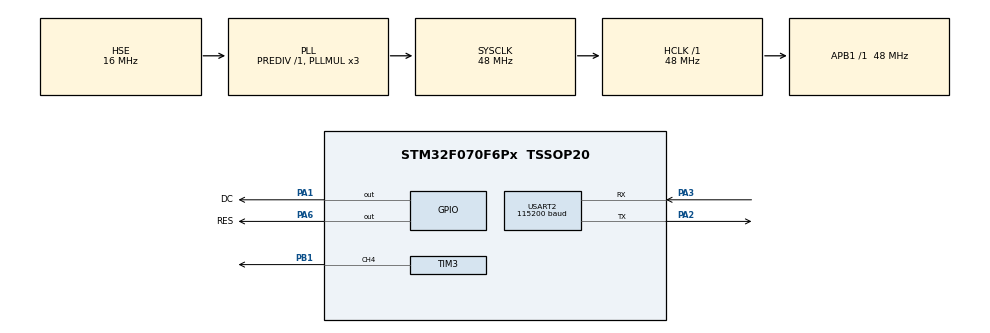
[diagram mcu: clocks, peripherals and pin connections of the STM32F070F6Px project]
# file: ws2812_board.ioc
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Dma.Request0=TIM3_CH4/UP
Dma.TIM3_CH4/UP.0.Direction=DMA_MEMORY_TO_PERIPH
Dma.TIM3_CH4/UP.0.Instance=DMA1_Channel3
Dma.TIM3_CH4/UP.0.MemDataAlignment=DMA_MDATAALIGN_WORD
Dma.TIM3_CH4/UP.0.MemInc=DMA_MINC_ENABLE
Dma.TIM3_CH4/UP.0.Mode=DMA_NORMAL
Dma.TIM3_CH4/UP.0.PeriphDataAlignment=DMA_PDATAALIGN_WORD
Dma.TIM3_CH4/UP.0.PeriphInc=DMA_PINC_DISABLE
Dma.TIM3_CH4/UP.0.Priority=DMA_PRIORITY_VERY_HIGH
Mcu.Family=STM32F0
Mcu.Name=STM32F070F6Px
Mcu.Package=TSSOP20
NVIC.DMA1_Channel2_3_IRQn=true\:0\:0\:false\:false\:true\:false\:true
NVIC.TIM3_IRQn=true\:0\:0\:false\:false\:true\:true\:true
PA1.GPIO_Label=DC
PA1.GPIO_Speed=GPIO_SPEED_FREQ_HIGH
PA1.Signal=GPIO_Output
PA13.Mode=Serial_Wire
PA13.Signal=SYS_SWDIO
PA14.Mode=Serial_Wire
PA14.Signal=SYS_SWCLK
PA2.Mode=Asynchronous
PA2.Signal=USART2_TX
PA3.Mode=Asynchronous
PA3.Signal=USART2_RX
PA6.GPIO_Label=RES
PA6.GPIO_Speed=GPIO_SPEED_FREQ_HIGH
PA6.Signal=GPIO_Output
PB1.Signal=S_TIM3_CH4
PF0-OSC_IN.Mode=HSE-External-Oscillator
PF0-OSC_IN.Signal=RCC_OSC_IN
PF1-OSC_OUT.Mode=HSE-External-Oscillator
PF1-OSC_OUT.Signal=RCC_OSC_OUT
ProjectManager.HeapSize=0x0
ProjectManager.StackSize=0x400
ProjectManager.TargetToolchain=MDK-ARM V5.32
RCC.AHBFreq_Value=48000000
RCC.APB1Freq_Value=48000000
RCC.APB1TimFreq_Value=48000000
RCC.HCLKFreq_Value=48000000
RCC.HSE_VALUE=16000000
RCC.PLLMUL=RCC_PLL_MUL3
RCC.PLLSourceVirtual=RCC_PLLSOURCE_HSE
RCC.SYSCLKFreq_VALUE=48000000
RCC.SYSCLKSource=RCC_SYSCLKSOURCE_PLLCLK
SH.S_TIM3_CH4.0=TIM3_CH4,PWM Generation4 CH4
TIM3.Channel-PWM\ Generation4\ CH4=TIM_CHANNEL_4
TIM3.Period=60-1
TIM3.Prescaler=1-1
USART2.BaudRate=115200
USART2.DMADisableonRxErrorParam=ADVFEATURE_DMA_DISABLEONRXERROR
USART2.VirtualMode-Asynchronous=VM_ASYNC
VP_TIM3_VS_ClockSourceINT.Mode=Internal
board=custom

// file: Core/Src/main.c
/* USER CODE BEGIN Header */
/**
  ******************************************************************************
  * @file           : main.c
  * @brief          : Main program body
  ******************************************************************************
  * @attention
  *
  * <h2><center>&copy; Copyright (c) 2021 STMicroelectronics.
  * All rights reserved.</center></h2>
  *
  * This software component is licensed by ST under BSD 3-Clause license,
  * the "License"; You may not use this file except in compliance with the
  * License. You may obtain a copy of the License at:
  *                        opensource.org/licenses/BSD-3-Clause
  *
  ******************************************************************************
  */
/* USER CODE END Header */
#include "main.h"
#include "dma.h"
#include "tim.h"
#include "usart.h"
#include "gpio.h"

/* USER CODE BEGIN Includes */
#include "ws2812b.h"
/* USER CODE END Includes */

/* USER CODE BEGIN PV */
ws2812b_t MyWs2812;
/* USER CODE END PV */

void SystemClock_Config(void);

int main(void)
{

  /* MCU Configuration--------------------------------------------------------*/

  /* Reset of all peripherals, Initializes the Flash interface and the Systick. */
  HAL_Init();

  /* Configure the system clock */
  SystemClock_Config();

  /* Initialize all configured peripherals */
  MX_GPIO_Init();
  MX_DMA_Init();
  MX_TIM3_Init();
  MX_USART2_UART_Init();
  /* USER CODE BEGIN 2 */
	HAL_TIM_PWM_Init(&htim3);
    uint8_t t;
    //OLED_Init();
    t=' ';

  /* USER CODE END 2 */

  /* Infinite loop */
  /* USER CODE BEGIN WHILE */
  while (1)
  {

    /* Infinite loop */
	  for(int i=1;i<=32;i++){
		  for(int j=0;j<i;j++)
		  {
			  SetLedColor(&MyWs2812,j,0,0,0);
		  }
	  SetLedColor(&MyWs2812,i,255,255,255);
      Ws2812bUpdate();
      HAL_Delay(60);
	  }
	  SetLedColor(&MyWs2812,32,0,0,0);
	  Ws2812bUpdate();
//    		OLED_Clear();
//	//	LED_ON;
//		OLED_ShowCHinese(0,0,0);//�?
//		OLED_ShowCHinese(18,0,1);//�?
//		OLED_ShowCHinese(36,0,2);//�?
//		OLED_ShowCHinese(54,0,3);//�?
//		OLED_ShowCHinese(72,0,4);//�?
//		OLED_ShowCHinese(90,0,5);//�?
//		OLED_ShowCHinese(108,0,6);//�?
//		OLED_ShowString(0,3,"1.3' OLED TEST");
//		//OLED_ShowString(8,2,"ZHONGJINGYUAN");
//	 //	OLED_ShowString(20,4,"2014/05/01");
//		OLED_ShowString(0,6,"ASCII:");
//		OLED_ShowString(63,6,"CODE:");
//		OLED_ShowChar(48,6,t);//显示ASCII字符
//		t++;
//		if(t>'~')t=' ';
//		OLED_ShowNum(103,6,t,3,16);//显示ASCII字符的码�?
//		HAL_Delay(1000);
    /* USER CODE END WHILE */

  }
}

void SystemClock_Config(void)
{
  RCC_OscInitTypeDef RCC_OscInitStruct = {0};
  RCC_ClkInitTypeDef RCC_ClkInitStruct = {0};

  /** Initializes the RCC Oscillators according to the specified parameters
  * in the RCC_OscInitTypeDef structure.
  */
  RCC_OscInitStruct.OscillatorType = RCC_OSCILLATORTYPE_HSE;
  RCC_OscInitStruct.HSEState = RCC_HSE_ON;
  RCC_OscInitStruct.PLL.PLLState = RCC_PLL_ON;
  RCC_OscInitStruct.PLL.PLLSource = RCC_PLLSOURCE_HSE;
  RCC_OscInitStruct.PLL.PLLMUL = RCC_PLL_MUL3;
  RCC_OscInitStruct.PLL.PREDIV = RCC_PREDIV_DIV1;
  if (HAL_RCC_OscConfig(&RCC_OscInitStruct) != HAL_OK)
  {
    Error_Handler();
  }
  /** Initializes the CPU, AHB and APB buses clocks
  */
  RCC_ClkInitStruct.ClockType = RCC_CLOCKTYPE_HCLK|RCC_CLOCKTYPE_SYSCLK
                              |RCC_CLOCKTYPE_PCLK1;
  RCC_ClkInitStruct.SYSCLKSource = RCC_SYSCLKSOURCE_PLLCLK;
  RCC_ClkInitStruct.AHBCLKDivider = RCC_SYSCLK_DIV1;
  RCC_ClkInitStruct.APB1CLKDivider = RCC_HCLK_DIV1;

  if (HAL_RCC_ClockConfig(&RCC_ClkInitStruct, FLASH_LATENCY_1) != HAL_OK)
  {
    Error_Handler();
  }
}

void Error_Handler(void)
{
  __disable_irq();
  while (1)
  {
  }
}

/************************ (C) COPYRIGHT STMicroelectronics *****END OF FILE****/
